# PIC32MK1024GPL100 register map
Vendor: Microchip
Registers are 32-bit, read-write, no defined reset value unless marked. A register's access mark holds for its fields unless they carry their own. Addresses are absolute, and some are shared; only a register's first bit layout is shown; [hi:lo] are bit positions; {n}, {i} and the like mark numbered series.

## CMP5
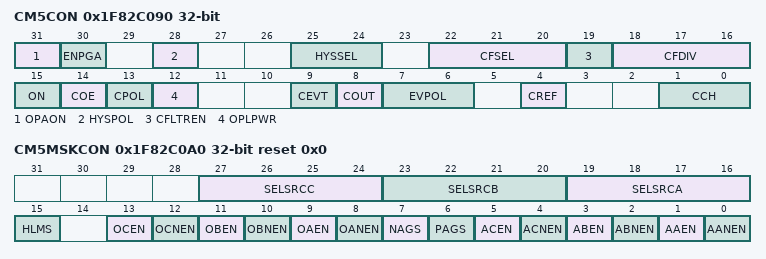
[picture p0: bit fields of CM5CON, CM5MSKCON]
0x1F82C090 CM5CON — (power-on value xx-x--00-00000000000--0000-0--00)
  [31] OPAON — Opamp Enable Bit
    1=Opamp Enabled and Connected to Pin; 0=Opamp is disabled and pin is released to other functions
  [30] ENPGA — Opamp Fixed Gain Enable bit
    1=Op amp is operating in Fixed Gain 1X mode; 0=Op amp is operating in Open Loop Mode
  [28] HYSPOL — Comparator Hysteresis Polarity Selection
    1=Hysteresis on falling edge, rising edge is accurate; 0=Hysteresis on rising edge, falling edge is accurate
  [25:24] HYSSEL
  [22:20] CFSEL
  [19] CFLTREN
  [18:16] CFDIV
  [15] ON
  [14] COE
  [13] CPOL
  [12] OPLPWR
  [9] CEVT
  [8] COUT ro
  [7:6] EVPOL
  [4] CREF
  [1:0] CCH
0x1F82C0A0 CM5MSKCON reset 0x0
  [27:24] SELSRCC, [23:20] SELSRCB, [19:16] SELSRCA, [15] HLMS, [13] OCEN, [12] OCNEN, [11] OBEN, [10] OBNEN, [9] OAEN, [8] OANEN, [7] NAGS, [6] PAGS, [5] ACEN, [4] ACNEN, [3] ABEN, [2] ABNEN, [1] AAEN, [0] AANEN

## CDAC1
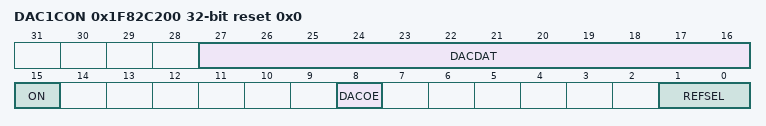
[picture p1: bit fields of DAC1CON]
0x1F82C200 DAC1CON reset 0x0 — CDAC Control Register
  [27:16] DACDAT — Data Input Register Bits for the CDAC
  [15] ON — CDAC Enable
    0=The CDAC is Disabled; 1=The CDAC is Enabled
  [8] DACOE — CDAC Output Enable
    0=Output is Disabled; drive to pin is floating; 1=Output is Enabled; CDAC voltage is connected to the pin
  [1:0] REFSEL — Reference Source Select
    0=No Reference Selected (no current consumed); 1=Positive Reference Voltage = External Vref+ Pin; 2=Positive Reference Voltage = 2 * Internal Bandgap Reference Voltage; 3=Positive Reference Voltage = AVdd

## CTMU
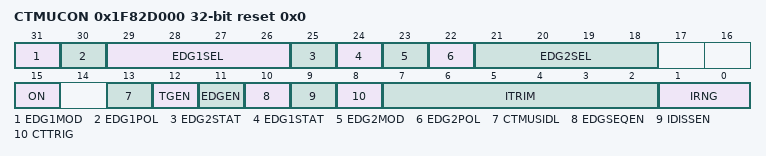
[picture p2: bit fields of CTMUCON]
0x1F82D000 CTMUCON reset 0x0
  [31] EDG1MOD, [30] EDG1POL, [29:26] EDG1SEL, [25] EDG2STAT, [24] EDG1STAT, [23] EDG2MOD, [22] EDG2POL, [21:18] EDG2SEL, [15] ON, [13] CTMUSIDL, [12] TGEN, [11] EDGEN, [10] EDGSEQEN, [9] IDISSEN, [8] CTTRIG, [7:2] ITRIM, [1:0] IRNG

## PMP
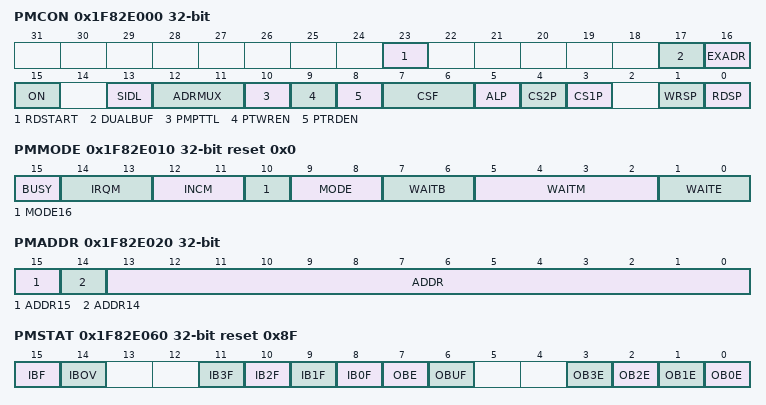
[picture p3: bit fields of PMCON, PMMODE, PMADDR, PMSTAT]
0x1F82E000 PMCON — (power-on value --------x-----xx00000-0000000-00)
  [23] RDSTART, [17] DUALBUF, [16] EXADR, [15] ON, [13] SIDL, [12:11] ADRMUX, [10] PMPTTL, [9] PTWREN, [8] PTRDEN, [7:6] CSF, [5] ALP, [4] CS2P, [3] CS1P, [1] WRSP, [0] RDSP
0x1F82E010 PMMODE reset 0x0
  [15] BUSY, [14:13] IRQM, [12:11] INCM, [10] MODE16, [9:8] MODE, [7:6] WAITB, [5:2] WAITM, [1:0] WAITE
0x1F82E020 PMADDR — (power-on value ----------------xxxxxxxxxxxxxxxx)
  [15] ADDR15, [14] ADDR14, [13:0] ADDR
0x1F82E030 PMDOUT — (power-on value xxxxxxxxxxxxxxxxxxxxxxxxxxxxxxxx)
  [31:0] DATAOUT
0x1F82E040 PMDIN — (power-on value xxxxxxxxxxxxxxxxxxxxxxxxxxxxxxxx)
  [31:0] DATAIN
0x1F82E050 PMAEN — (power-on value --------xxxxxxxxxxxxxxxxxxxxxxxx)
  [23:0] PTEN
0x1F82E060 PMSTAT reset 0x8F
  [15] IBF ro, [14] IBOV, [n+8] IB{n}F ro (n=0..3), [7] OBE ro, [6] OBUF, [n] OB{n}E ro (n=0..3)
0x1F82E070 PMWADDR — (power-on value --------xxxxxxxxxxxxxxxxxxxxxxxx)
  [23:0] WADDR
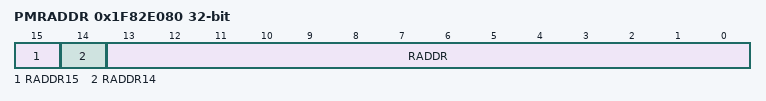
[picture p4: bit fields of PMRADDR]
0x1F82E080 PMRADDR — (power-on value ----------------xxxxxxxxxxxxxxxx)
  [15] RADDR15, [14] RADDR14, [13:0] RADDR
0x1F82E090 PMRDIN — (power-on value xxxxxxxxxxxxxxxxxxxxxxxxxxxxxxxx)
  [31:0] RDATAIN

## ICAP10
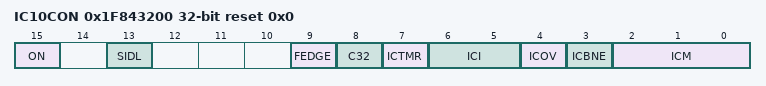
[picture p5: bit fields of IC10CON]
0x1F843200 IC10CON reset 0x0
  [15] ON, [13] SIDL, [9] FEDGE, [8] C32, [7] ICTMR, [6:5] ICI, [4] ICOV ro, [3] ICBNE ro, [2:0] ICM
0x1F843210 IC10BUF ro — (power-on value xxxxxxxxxxxxxxxxxxxxxxxxxxxxxxxx)

## ICAP11
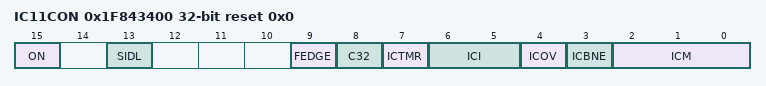
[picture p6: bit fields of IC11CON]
0x1F843400 IC11CON reset 0x0
  [15] ON, [13] SIDL, [9] FEDGE, [8] C32, [7] ICTMR, [6:5] ICI, [4] ICOV ro, [3] ICBNE ro, [2:0] ICM
0x1F843410 IC11BUF ro — (power-on value xxxxxxxxxxxxxxxxxxxxxxxxxxxxxxxx)

## ICAP12
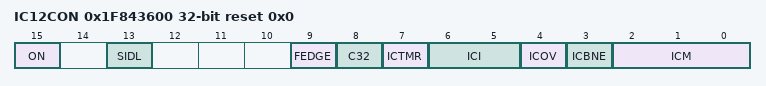
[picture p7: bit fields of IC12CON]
0x1F843600 IC12CON reset 0x0
  [15] ON, [13] SIDL, [9] FEDGE, [8] C32, [7] ICTMR, [6:5] ICI, [4] ICOV ro, [3] ICBNE ro, [2:0] ICM
0x1F843610 IC12BUF ro — (power-on value xxxxxxxxxxxxxxxxxxxxxxxxxxxxxxxx)
